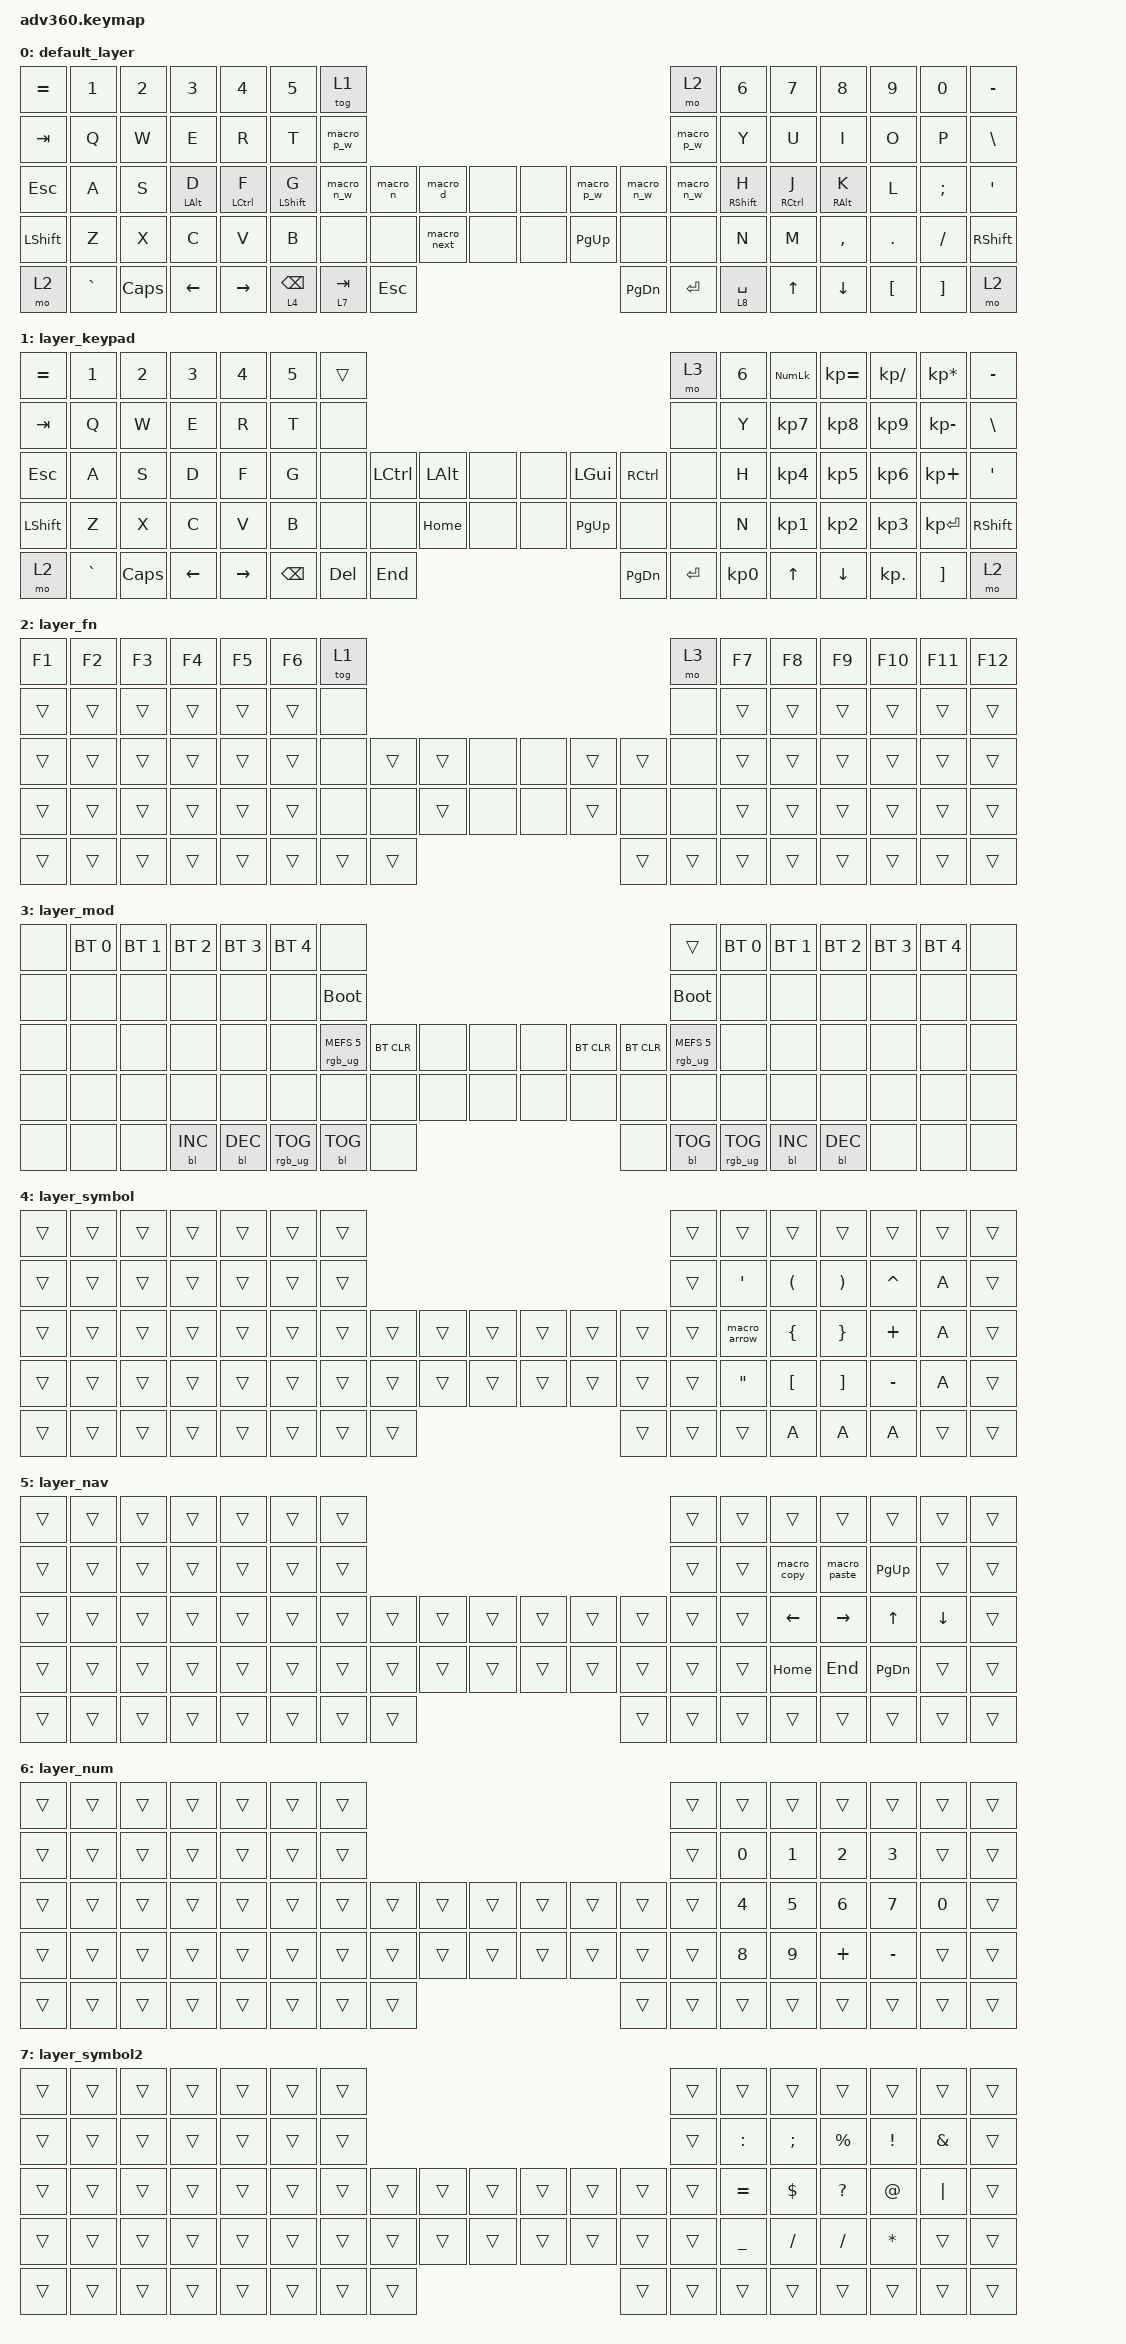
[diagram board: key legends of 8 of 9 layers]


/*
 * Copyright (c) 2020 The ZMK Contributors
 *
 * SPDX-License-Identifier: MIT
 */


/* THIS FILE WAS GENERATED!
 *
 * This file was generated automatically. You may or may not want to
 * edit it directly.
 */

#include <behaviors.dtsi>
#include <dt-bindings/zmk/keys.h>
#include <dt-bindings/zmk/bt.h>
#include <dt-bindings/zmk/rgb.h>
#include <dt-bindings/zmk/backlight.h>

#define KEYS_LEFT 0 1 2 3 4 5 6 \
                  14 15 16 17 18 19 20 \
                  28 29 30 31 32 33 34 \
                  46 47 48 49 50 51 \
                  66 67 68 69 70

#define KEYS_RIGHT 7 8 9 10 11 12 13 \
                   21 22 23 24 25 26 27 \
                   39 40 41 42 43 44 45 \
                   60 61 62 63 64 65 \
                   77 78 79 80 81

#define THUMBS_LEFT 35 36 54 71 72 73

#define THUMBS_RIGHT 37 38 57 74 75 76

#define THUMBS THUMBS_LEFT THUMBS_RIGHT

&lt {
    quick-tap-ms = <300>;
    global-quick-tap;
};


/ {
  behaviors {
    #include "macros.dtsi"

    hm: homerow_mods {
        compatible = "zmk,behavior-hold-tap";
        label = "HOMEROW_MODS";
        #binding-cells = <2>;
        tapping-term-ms = <185>;
        quick_tap_ms = <500>;
        flavor = "balanced";
        bindings = <&kp>, <&kp>;
    };

    hm_l: homerow_mods_left {
        compatible = "zmk,behavior-hold-tap";
        label = "HOMEROW_MODS_LEFT";
        #binding-cells = <2>;
        tapping-term-ms = <185>;
        quick_tap_ms = <500>;
        flavor = "tap-preferred";
        bindings = <&kp>, <&kp>;
        hold-trigger-key-positions = <KEYS_RIGHT THUMBS>;
    };

    hm_r: homerow_mods_right {
        compatible = "zmk,behavior-hold-tap";
        label = "HOMEROW_MODS_RIGHT";
        #binding-cells = <2>;
        tapping-term-ms = <185>;
        quick_tap_ms = <500>;
        flavor = "tap-preferred";
        bindings = <&kp>, <&kp>;
        hold-trigger-key-positions = <KEYS_LEFT THUMBS>;
    };

/*
    lh_pht: left_hand_positional_hold_tap {
            compatible = "zmk,behavior-hold-tap";
            label = "LEFT_POSITIONAL_HOLD_TAP";
            #binding-cells = <2>;
            flavor = "tap-unless-interrupted";
            tapping-term-ms = <100>;                        // <---[[produces tap if held longer than tapping-term-ms]]
            quick-tap-ms = <200>;
            bindings = <&kp>, <&kp>;
            hold-trigger-key-positions = <22 23 24 25 26 42 43 44 45 46 59 62 63 64 65 72 73 74 75 76 77 78>;    // <---[[right-hand keys]]
        };
    
    rh_pht: right_hand_positional_hold_tap {
            compatible = "zmk,behavior-hold-tap";
            label = "RIGHT_POSITIONAL_HOLD_TAP";
            #binding-cells = <2>;
            flavor = "tap-unless-interrupted";
            tapping-term-ms = <150>;                        // <---[[produces tap if held longer than tapping-term-ms]]
            quick-tap-ms = <200>;
            bindings = <&kp>, <&kp>;
            hold-trigger-key-positions = <15 16 17 18 19 29 30 31 32 33 49 50 51 52 53 59 73 73 74 75 76 77 78>;    // <---[[right-hand keys]]
        };

*/


  };

    keymap {
        compatible = "zmk,keymap";


        default_layer {
            bindings = <
 &kp EQUAL     &kp N1    &kp N2          &kp N3       &kp N4            &kp N5                     &tog 1                                                                     &mo 2             &kp N6       &kp N7           &kp N8    &kp N9    &kp N0  &kp MINUS
   &kp TAB      &kp Q     &kp W           &kp E        &kp R             &kp T                       &macro_p_w                                                                 &macro_p_w              &kp Y        &kp U            &kp I     &kp O     &kp P   &kp BSLH
   &kp ESC      &kp A     &kp S  &hm_l LEFT_ALT D  &hm_l LCTRL F  &hm_l LEFT_SHIFT G                       &macro_n_w  &macro_n    &macro_d   &none   &none    &macro_p_w   &macro_n_w   &macro_n_w  &hm_r RIGHT_SHIFT H  &hm_r RCTRL J  &hm_r RIGHT_ALT K     &kp L  &kp SEMI    &kp SQT
 &kp LSHFT      &kp Z     &kp X           &kp C        &kp V             &kp B                      &none      &none    &macro_next   &none   &none  &kp PG_UP      &none        &none              &kp N        &kp M        &kp COMMA   &kp DOT  &kp FSLH  &kp RSHFT
     &mo 2  &kp GRAVE  &kp CAPS        &kp LEFT    &kp RIGHT                              &lt 4 BACKSPACE  &lt 7 TAB  &kp ESCAPE                  &kp PG_DN  &kp ENTER    &lt 8 SPACE                          &kp UP         &kp DOWN  &kp LBKT  &kp RBKT      &mo 2
            >;
        };

        layer_keypad {
            bindings = <
 &kp EQUAL     &kp N1    &kp N2    &kp N3     &kp N4  &kp N5              &trans                                                                 &mo 3  &kp N6  &kp KP_NUM  &kp KP_EQUAL  &kp KP_DIVIDE  &kp KP_MULTIPLY  &kp MINUS
   &kp TAB      &kp Q     &kp W     &kp E      &kp R   &kp T               &none                                                                 &none   &kp Y   &kp KP_N7     &kp KP_N8      &kp KP_N9     &kp KP_MINUS   &kp BSLH
   &kp ESC      &kp A     &kp S     &kp D      &kp F   &kp G               &none  &kp LCTRL  &kp LALT   &none   &none   &kp LGUI  &kp RCTRL      &none   &kp H   &kp KP_N4     &kp KP_N5      &kp KP_N6      &kp KP_PLUS    &kp SQT
 &kp LSHFT      &kp Z     &kp X     &kp C      &kp V   &kp B               &none      &none  &kp HOME   &none   &none  &kp PG_UP      &none      &none   &kp N   &kp KP_N1     &kp KP_N2      &kp KP_N3     &kp KP_ENTER  &kp RSHFT
     &mo 2  &kp GRAVE  &kp CAPS  &kp LEFT  &kp RIGHT                    &kp BSPC    &kp DEL   &kp END                  &kp PG_DN  &kp ENTER  &kp KP_N0              &kp UP      &kp DOWN     &kp KP_DOT         &kp RBKT      &mo 2
            >;
        };

        layer_fn {
            bindings = <
 &kp F1  &kp F2  &kp F3  &kp F4  &kp F5  &kp F6            &tog 1                                                   &mo 3  &kp F7  &kp F8  &kp F9  &kp F10  &kp F11  &kp F12
 &trans  &trans  &trans  &trans  &trans  &trans             &none                                                   &none  &trans  &trans  &trans   &trans   &trans   &trans
 &trans  &trans  &trans  &trans  &trans  &trans             &none  &trans  &trans   &none   &none  &trans  &trans   &none  &trans  &trans  &trans   &trans   &trans   &trans
 &trans  &trans  &trans  &trans  &trans  &trans             &none   &none  &trans   &none   &none  &trans   &none   &none  &trans  &trans  &trans   &trans   &trans   &trans
 &trans  &trans  &trans  &trans  &trans                    &trans  &trans  &trans                  &trans  &trans  &trans          &trans  &trans   &trans   &trans   &trans
            >;
        };

        layer_mod {
            bindings = <
  &none  &bt BT_SEL 0  &bt BT_SEL 1  &bt BT_SEL 2  &bt BT_SEL 3  &bt BT_SEL 4                             &none                                                                              &trans  &bt BT_SEL 0  &bt BT_SEL 1  &bt BT_SEL 2  &bt BT_SEL 3  &bt BT_SEL 4   &none
  &none         &none         &none         &none         &none         &none                       &bootloader                                                                         &bootloader         &none         &none         &none         &none         &none   &none
  &none         &none         &none         &none         &none         &none            &rgb_ug RGB_MEFS_CMD 5  &bt BT_CLR   &none   &none   &none  &bt BT_CLR  &bt BT_CLR  &rgb_ug RGB_MEFS_CMD 5         &none         &none         &none         &none         &none   &none
  &none         &none         &none         &none         &none         &none                             &none       &none   &none   &none   &none       &none       &none                   &none         &none         &none         &none         &none         &none   &none
  &none         &none         &none    &bl BL_INC    &bl BL_DEC                                 &rgb_ug RGB_TOG  &bl BL_TOG   &none                       &none  &bl BL_TOG         &rgb_ug RGB_TOG                  &bl BL_INC    &bl BL_DEC         &none         &none   &none
            >;
        };

        layer_symbol {
            bindings = <
 &trans  &trans  &trans  &trans  &trans  &trans            &trans                                                  &trans             &trans                &trans                 &trans     &trans  &trans  &trans
 &trans  &trans  &trans  &trans  &trans  &trans            &trans                                                  &trans   &kp SINGLE_QUOTE  &kp LEFT_PARENTHESIS  &kp RIGHT_PARENTHESIS  &kp CARET   &kp A  &trans
 &trans  &trans  &trans  &trans  &trans  &trans            &trans  &trans  &trans  &trans  &trans  &trans  &trans  &trans       &macro_arrow        &kp LEFT_BRACE        &kp RIGHT_BRACE   &kp PLUS   &kp A  &trans
 &trans  &trans  &trans  &trans  &trans  &trans            &trans  &trans  &trans  &trans  &trans  &trans  &trans  &trans  &kp DOUBLE_QUOTES      &kp LEFT_BRACKET      &kp RIGHT_BRACKET  &kp MINUS   &kp A  &trans
 &trans  &trans  &trans  &trans  &trans                    &trans  &trans  &trans                  &trans  &trans  &trans                                    &kp A                  &kp A      &kp A  &trans  &trans
            >;
        };

        layer_nav {
            bindings = <
 &trans  &trans  &trans  &trans  &trans  &trans            &trans                                                  &trans  &trans          &trans           &trans         &trans          &trans  &trans
 &trans  &trans  &trans  &trans  &trans  &trans            &trans                                                  &trans  &trans     &macro_copy     &macro_paste    &kp PAGE_UP          &trans  &trans
 &trans  &trans  &trans  &trans  &trans  &trans            &trans  &trans  &trans  &trans  &trans  &trans  &trans  &trans  &trans  &kp LEFT_ARROW  &kp RIGHT_ARROW   &kp UP_ARROW  &kp DOWN_ARROW  &trans
 &trans  &trans  &trans  &trans  &trans  &trans            &trans  &trans  &trans  &trans  &trans  &trans  &trans  &trans  &trans        &kp HOME          &kp END  &kp PAGE_DOWN          &trans  &trans
 &trans  &trans  &trans  &trans  &trans                    &trans  &trans  &trans                  &trans  &trans  &trans                  &trans           &trans         &trans          &trans  &trans
            >;
        };

        layer_num {
            bindings = <
 &trans  &trans  &trans  &trans  &trans  &trans            &trans                                                  &trans        &trans        &trans        &trans        &trans        &trans  &trans
 &trans  &trans  &trans  &trans  &trans  &trans            &trans                                                  &trans  &kp NUMBER_0  &kp NUMBER_1  &kp NUMBER_2  &kp NUMBER_3        &trans  &trans
 &trans  &trans  &trans  &trans  &trans  &trans            &trans  &trans  &trans  &trans  &trans  &trans  &trans  &trans  &kp NUMBER_4  &kp NUMBER_5  &kp NUMBER_6  &kp NUMBER_7  &kp NUMBER_0  &trans
 &trans  &trans  &trans  &trans  &trans  &trans            &trans  &trans  &trans  &trans  &trans  &trans  &trans  &trans  &kp NUMBER_8  &kp NUMBER_9      &kp PLUS     &kp MINUS        &trans  &trans
 &trans  &trans  &trans  &trans  &trans                    &trans  &trans  &trans                  &trans  &trans  &trans                      &trans        &trans        &trans        &trans  &trans
            >;
        };

        layer_symbol2 {
            bindings = <
 &trans  &trans  &trans  &trans  &trans  &trans            &trans                                                  &trans          &trans         &trans        &trans        &trans         &trans  &trans
 &trans  &trans  &trans  &trans  &trans  &trans            &trans                                                  &trans       &kp COLON  &kp SEMICOLON   &kp PERCENT      &kp EXCL  &kp AMPERSAND  &trans
 &trans  &trans  &trans  &trans  &trans  &trans            &trans  &trans  &trans  &trans  &trans  &trans  &trans  &trans       &kp EQUAL     &kp DOLLAR  &kp QUESTION   &kp AT_SIGN       &kp PIPE  &trans
 &trans  &trans  &trans  &trans  &trans  &trans            &trans  &trans  &trans  &trans  &trans  &trans  &trans  &trans  &kp UNDERSCORE   &kp SLASH     &kp SLASH  &kp ASTERISK         &trans  &trans
 &trans  &trans  &trans  &trans  &trans                    &trans  &trans  &trans                  &trans  &trans  &trans                         &trans        &trans        &trans         &trans  &trans
            >;
        };
layer_fn2 {
    bindings = <
        &trans &trans &trans &trans &trans &trans &trans &trans &trans &trans &trans &trans &trans &trans
        &trans &kp F1 &kp F2 &kp F3 &kp F4 &kp F5 &trans &trans &trans &trans &trans &trans &trans &trans
        &trans &kp F6 &kp F7 &kp F8 &kp F9 &kp F10 &trans &trans &trans &trans &trans &trans &trans &trans
        &trans &kp F11 &kp F12 &kp F13 &kp F14 &kp F15 &trans &trans &trans &trans &trans &trans &trans &trans
        &trans &trans &trans &trans &trans &trans &trans &trans &trans &trans &trans &trans &trans &trans
    >;
};
    };
};
